AUTOSAR XML (schema 4-3-1)
standard types defined: uint8, uint8_DataConstr
package /ComponentTypes
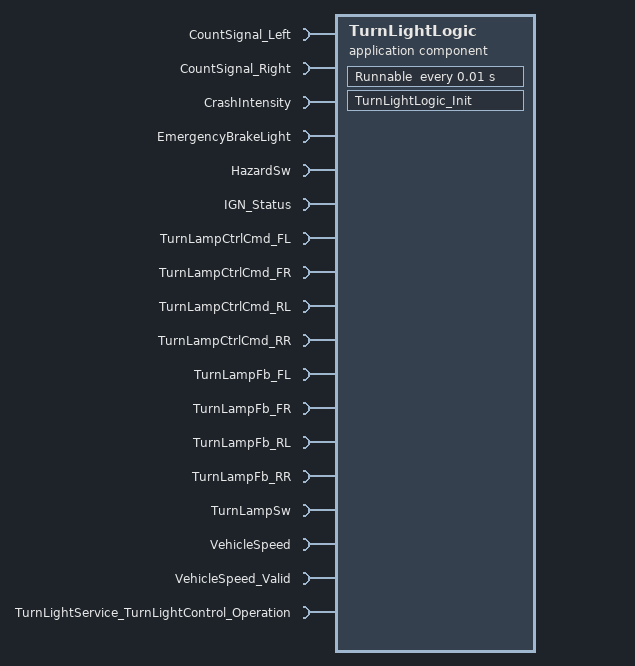
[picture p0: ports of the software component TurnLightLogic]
  application sw component type TurnLightLogic
    18 x require port:
      CountSignal_Left: nonqueued-receiver-com-spec{data-element=CountSignal_Left/Signal, init-value=ComSpecd2203bb2_a13daf129cd7b46c:0}, required-interface=CountSignal_Left
      CountSignal_Right: nonqueued-receiver-com-spec{data-element=CountSignal_Right/Signal, init-value=ComSpec03440295_2dc0fdc3ac70e9d6:0}, required-interface=CountSignal_Right
      CrashIntensity: nonqueued-receiver-com-spec{data-element=CrashIntensity/Signal, init-value=ComSpec2a2e3b47_23d1c5127052defe:0}, required-interface=CrashIntensity
      EmergencyBrakeLight: nonqueued-receiver-com-spec{data-element=EmergencyBrakeLight/Signal, init-value=ComSpec0afcefb2_ef366aa8cb1f03cb:0}, required-interface=EmergencyBrakeLight
      HazardSw: nonqueued-receiver-com-spec{data-element=HazardSw/Signal, init-value=ComSpec01d57de5_b175151daf845da3:0}, required-interface=HazardSw
      IGN_Status: nonqueued-receiver-com-spec{data-element=IGN_Status/Signal, init-value=ComSpec9be9e261_47bd01cc7e10d1ac:0}, required-interface=IGN_Status
      TurnLampCtrlCmd_FL: nonqueued-receiver-com-spec{data-element=TurnLampCtrlCmd_FL/Signal, init-value=ComSpec5a75f40d_b9ba2ddbe8769e5c:0}, required-interface=TurnLampCtrlCmd_FL
      TurnLampCtrlCmd_FR: nonqueued-receiver-com-spec{data-element=TurnLampCtrlCmd_FR/Signal, init-value=ComSpecfa6fc74f_23e59cdc98d21e45:0}, required-interface=TurnLampCtrlCmd_FR
      TurnLampCtrlCmd_RL: nonqueued-receiver-com-spec{data-element=TurnLampCtrlCmd_RL/Signal, init-value=ComSpecf46d02e7_9bf3e6533e85e486:0}, required-interface=TurnLampCtrlCmd_RL
      TurnLampCtrlCmd_RR: nonqueued-receiver-com-spec{data-element=TurnLampCtrlCmd_RR/Signal, init-value=ComSpec394c1ac3_9d731bd9322b2882:0}, required-interface=TurnLampCtrlCmd_RR
      TurnLampFb_FL: nonqueued-receiver-com-spec{data-element=TurnLampFb_FL/Signal, init-value=ComSpec2b728769_f659241e33fc0d94:0}, required-interface=TurnLampFb_FL
      TurnLampFb_FR: nonqueued-receiver-com-spec{data-element=TurnLampFb_FR/Signal, init-value=ComSpecd3adec8f_575c8037535f14d5:0}, required-interface=TurnLampFb_FR
      TurnLampFb_RL: nonqueued-receiver-com-spec{data-element=TurnLampFb_RL/Signal, init-value=ComSpec4345c889_3bcdc03ada2720c4:0}, required-interface=TurnLampFb_RL
      TurnLampFb_RR: nonqueued-receiver-com-spec{data-element=TurnLampFb_RR/Signal, init-value=ComSpec85f6b6c2_72a1d895d6c3a144:0}, required-interface=TurnLampFb_RR
      TurnLampSw: nonqueued-receiver-com-spec{data-element=TurnLampSw/Signal, init-value=ComSpeca9d371a6_cbb0ffc7a3961cf3:0}, required-interface=TurnLampSw
      VehicleSpeed: nonqueued-receiver-com-spec{data-element=VehicleSpeed/Signal, init-value=ComSpecb9c98c1f_8c2ebcb1193d6767:0}, required-interface=VehicleSpeed
      VehicleSpeed_Valid: nonqueued-receiver-com-spec{data-element=VehicleSpeed_Valid/Signal, init-value=ComSpec0c300511_5bcd319f29bdd2fa:0}, required-interface=VehicleSpeed_Valid
      TurnLightService_TurnLightControl_Operation: required-interface=TurnLightService_TurnLightControl_Operation
    behavior TurnLightLogic_InternalBehavior: data-type-mapping=TurnLightLogicDataTypeMappingsSet, handle-termination-and-restart=NO-SUPPORT
      timing event TMT_Runnable: start-on-event=Runnable, period=0.01
      runnable Runnable
        data-receive-point-by-arguments:
          17 x access:
            IN_CountSignal_Left_Signal: accessed-variable=CountSignal_Left.Signal
            IN_CountSignal_Right_Signal: accessed-variable=CountSignal_Right.Signal
            IN_CrashIntensity_Signal: accessed-variable=CrashIntensity.Signal
            IN_EmergencyBrakeLight_Signal: accessed-variable=EmergencyBrakeLight.Signal
            IN_HazardSw_Signal: accessed-variable=HazardSw.Signal
            IN_IGN_Status_Signal: accessed-variable=IGN_Status.Signal
            IN_TurnLampCtrlCmd_FL_Signal: accessed-variable=TurnLampCtrlCmd_FL.Signal
            IN_TurnLampCtrlCmd_FR_Signal: accessed-variable=TurnLampCtrlCmd_FR.Signal
            IN_TurnLampCtrlCmd_RL_Signal: accessed-variable=TurnLampCtrlCmd_RL.Signal
            IN_TurnLampCtrlCmd_RR_Signal: accessed-variable=TurnLampCtrlCmd_RR.Signal
            IN_TurnLampFb_FL_Signal: accessed-variable=TurnLampFb_FL.Signal
            IN_TurnLampFb_FR_Signal: accessed-variable=TurnLampFb_FR.Signal
            IN_TurnLampFb_RL_Signal: accessed-variable=TurnLampFb_RL.Signal
            IN_TurnLampFb_RR_Signal: accessed-variable=TurnLampFb_RR.Signal
            IN_TurnLampSw_Signal: accessed-variable=TurnLampSw.Signal
            IN_VehicleSpeed_Signal: accessed-variable=VehicleSpeed.Signal
            IN_VehicleSpeed_Valid_Signal: accessed-variable=VehicleSpeed_Valid.Signal
        sync call SC_TurnLightService_TurnLightControl_Operation_Operation: operation=TurnLightService_TurnLightControl_Operation.Operation, timeout=0
      runnable TurnLightLogic_Init
package /DataTypes
  impl type TurnLightService_Ctrl_Oeration: category=STRUCTURE
    7 x element, all with category=TYPE_REFERENCE, implementation-data-type=uint8:
      TurnLightPosition
      TurnLightOnOff
      TurnLightDutyCycle
      TurnLightCycle
      TurnLightTimes
      TurnLightNum
      TurnLightPriority
package /DataTypes/CompuMethods
  compu method TurnLightOnOff: 0=NOREQUEST, 1=OFF, 2=ON
  compu method TurnLightPosition: 0=NOREQUEST, 1=LEFT, 2=RIGHT, 3=ALL, 4=FRONT_LEFT, 5=MIDDLE_LEFT, 6=REAR_LEFT, 7=FRONT_RIGHT, 8=MIDDLE_RIGHT, 9=REAR_RIGHT
package /PortInterfaces
  client server interface TurnLightService_TurnLightControl_Operation
    operation Operation
      arg TurnLightCtrlPara: category=STRUCTURE, sw-calibration-access=READ-WRITE, type=TurnLightService, direction=IN
  17 x sender receiver interface:
    CountSignal_Left: invalidation-policy{data-element=CountSignal_Left/Signal, handle-invalid=DONT-INVALIDATE}
      data Signal: category=VALUE, type=uint8
    CountSignal_Right: invalidation-policy{data-element=CountSignal_Right/Signal, handle-invalid=DONT-INVALIDATE}
      data Signal: category=VALUE, type=uint8
    CrashIntensity: invalidation-policy{data-element=CrashIntensity/Signal, handle-invalid=DONT-INVALIDATE}
      data Signal: category=VALUE, type=uint8
    EmergencyBrakeLight: invalidation-policy{data-element=EmergencyBrakeLight/Signal, handle-invalid=DONT-INVALIDATE}
      data Signal: category=VALUE, type=uint8
    HazardSw: invalidation-policy{data-element=HazardSw/Signal, handle-invalid=DONT-INVALIDATE}
      data Signal: category=VALUE, type=uint8
    IGN_Status: invalidation-policy{data-element=IGN_Status/Signal, handle-invalid=DONT-INVALIDATE}
      data Signal: category=VALUE, type=uint8
    TurnLampCtrlCmd_FL: invalidation-policy{data-element=TurnLampCtrlCmd_FL/Signal, handle-invalid=DONT-INVALIDATE}
      data Signal: category=VALUE, type=uint8
    TurnLampCtrlCmd_FR: invalidation-policy{data-element=TurnLampCtrlCmd_FR/Signal, handle-invalid=DONT-INVALIDATE}
      data Signal: category=VALUE, type=uint8
    TurnLampCtrlCmd_RL: invalidation-policy{data-element=TurnLampCtrlCmd_RL/Signal, handle-invalid=DONT-INVALIDATE}
      data Signal: category=VALUE, type=uint8
    TurnLampCtrlCmd_RR: invalidation-policy{data-element=TurnLampCtrlCmd_RR/Signal, handle-invalid=DONT-INVALIDATE}
      data Signal: category=VALUE, type=uint8
    TurnLampFb_FL: invalidation-policy{data-element=TurnLampFb_FL/Signal, handle-invalid=DONT-INVALIDATE}
      data Signal: category=VALUE, type=uint8
    TurnLampFb_FR: invalidation-policy{data-element=TurnLampFb_FR/Signal, handle-invalid=DONT-INVALIDATE}
      data Signal: category=VALUE, type=uint8
    TurnLampFb_RL: invalidation-policy{data-element=TurnLampFb_RL/Signal, handle-invalid=DONT-INVALIDATE}
      data Signal: category=VALUE, type=uint8
    TurnLampFb_RR: invalidation-policy{data-element=TurnLampFb_RR/Signal, handle-invalid=DONT-INVALIDATE}
      data Signal: category=VALUE, type=uint8
    TurnLampSw: invalidation-policy{data-element=TurnLampSw/Signal, handle-invalid=DONT-INVALIDATE}
      data Signal: category=VALUE, type=uint8
    VehicleSpeed: invalidation-policy{data-element=VehicleSpeed/Signal, handle-invalid=DONT-INVALIDATE}
      data Signal: category=VALUE, type=uint8
    VehicleSpeed_Valid: invalidation-policy{data-element=VehicleSpeed_Valid/Signal, handle-invalid=DONT-INVALIDATE}
      data Signal: category=VALUE, type=uint8
